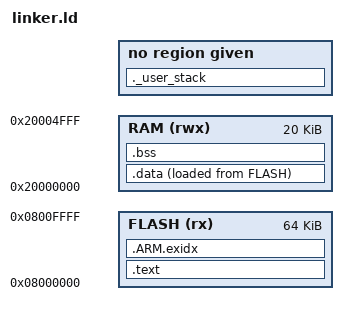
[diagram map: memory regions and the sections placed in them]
ENTRY(Reset_Handler)

MEMORY
{
  FLASH (rx) : ORIGIN = 0x08000000, LENGTH = 64K
  RAM   (rwx): ORIGIN = 0x20000000, LENGTH = 20K
}

SECTIONS
{
  .text : {
    KEEP(*(.isr_vector))
    *(.text*)
    *(.rodata*)
    KEEP(*(.init))
    KEEP(*(.fini))
  } > FLASH

  .ARM.exidx :
  {
    __exidx_start = .;
    *(.ARM.exidx* .gnu.linkonce.armexidx.*)
    __exidx_end = .;
  } > FLASH

  .data : {
    _sdata = .;
    *(.data*)
    _edata = .;
  } > RAM AT > FLASH

  .bss : {
    _sbss = .;
    *(.bss*)
    *(COMMON)
    _ebss = .;
  } > RAM

  ._user_stack :
  {
    . = ALIGN(8);
    _estack = ORIGIN(RAM) + LENGTH(RAM);
    _sidata = LOADADDR(.data);
  }

  end = .;
  _end = .;
}
